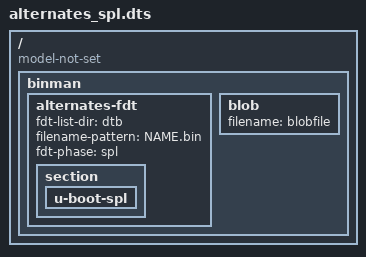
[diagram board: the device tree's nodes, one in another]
// SPDX-License-Identifier: GPL-2.0+
// Copyright 2024 Google LLC
// Written by Simon Glass <sjg@chromium.org>

/dts-v1/;

/ {
	#address-cells = <1>;
	#size-cells = <1>;

	compatible = "model-not-set";

	binman {
		alternates-fdt {
			fdt-list-dir = "dtb";
			filename-pattern = "NAME.bin";
			fdt-phase = "spl";

			section {
				u-boot-spl {
				};
			};
		};

		blob {
			filename = "blobfile";
		};
	};
};
